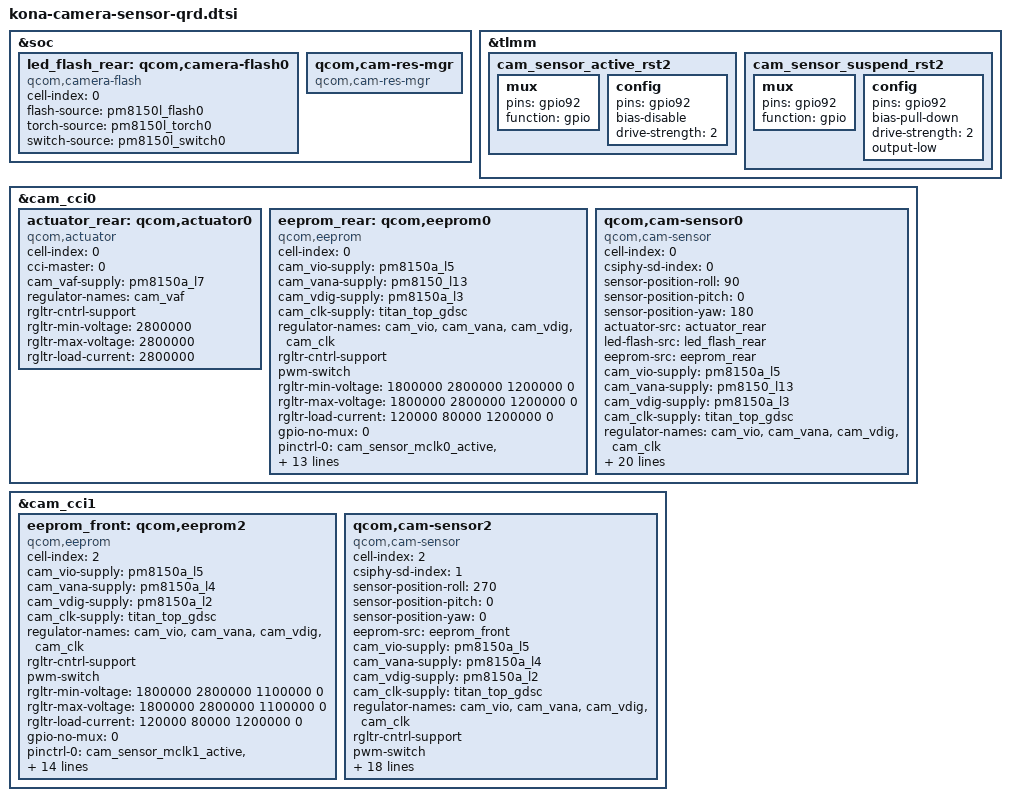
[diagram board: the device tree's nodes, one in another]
&soc {

	led_flash_rear: qcom,camera-flash0 {
		cell-index = <0>;
		compatible = "qcom,camera-flash";
		flash-source = <&pm8150l_flash0>;
		torch-source = <&pm8150l_torch0>;
		switch-source = <&pm8150l_switch0>;
		status = "ok";
	};

	qcom,cam-res-mgr {
		compatible = "qcom,cam-res-mgr";
		status = "ok";
	};
};

&tlmm {

	cam_sensor_active_rst2: cam_sensor_active_rst2 {
		mux {
			pins = "gpio92";
			function = "gpio";
		};

		config {
			pins = "gpio92";
			bias-disable;
			drive-strength = <2>;
		};
	};

	cam_sensor_suspend_rst2: cam_sensor_suspend_rst2 {
		mux {
			pins = "gpio92";
			function = "gpio";
		};

		config {
			pins = "gpio92";
			bias-pull-down;
			drive-strength = <2>;
			output-low;
		};
	};
};

&cam_cci0 {

	actuator_rear: qcom,actuator0 {
		cell-index = <0>;
		compatible = "qcom,actuator";
		cci-master = <0>;
		cam_vaf-supply = <&pm8150a_l7>;
		regulator-names = "cam_vaf";
		rgltr-cntrl-support;
		rgltr-min-voltage = <2800000>;
		rgltr-max-voltage = <2800000>;
		rgltr-load-current = <2800000>;
	};

	eeprom_rear: qcom,eeprom0 {
		cell-index = <0>;
		compatible = "qcom,eeprom";
		cam_vio-supply = <&pm8150a_l5>;
		cam_vana-supply = <&pm8150_l13>;
		cam_vdig-supply = <&pm8150a_l3>;
		cam_clk-supply = <&titan_top_gdsc>;
		regulator-names = "cam_vio", "cam_vana", "cam_vdig", "cam_clk";
		rgltr-cntrl-support;
		pwm-switch;
		rgltr-min-voltage = <1800000 2800000 1200000 0>;
		rgltr-max-voltage = <1800000 2800000 1200000 0>;
		rgltr-load-current = <120000 80000 1200000 0>;
		gpio-no-mux = <0>;
		pinctrl-names = "cam_default", "cam_suspend";
		pinctrl-0 = <&cam_sensor_mclk0_active>, <&cam_sensor_active_rear>;
		pinctrl-1 = <&cam_sensor_mclk0_suspend>, <&cam_sensor_suspend_rear>;
		gpios = <&tlmm 94 GPIO_ACTIVE_HIGH>, <&tlmm 93 GPIO_ACTIVE_HIGH>;
		gpio-reset = <1>;
		gpio-req-tbl-num = <0 1>;
		gpio-req-tbl-flags = <1 0>;
		gpio-req-tbl-label = "CAMIF_MCLK0", "CAM_RESET0";
		sensor-mode = <0>;
		cci-master = <0>;
		status = "ok";
		clocks = <&clock_camcc CAM_CC_MCLK0_CLK>;
		clock-names = "cam_clk";
		clock-cntl-level = "turbo";
		clock-rates = <24000000>;
	};

	qcom,cam-sensor0 {
		cell-index = <0>;
		compatible = "qcom,cam-sensor";
		csiphy-sd-index = <0>;
		sensor-position-roll = <90>;
		sensor-position-pitch = <0>;
		sensor-position-yaw = <180>;
		actuator-src = <&actuator_rear>;
		led-flash-src = <&led_flash_rear>;
		eeprom-src = <&eeprom_rear>;
		cam_vio-supply = <&pm8150a_l5>;
		cam_vana-supply = <&pm8150_l13>;
		cam_vdig-supply = <&pm8150a_l3>;
		cam_clk-supply = <&titan_top_gdsc>;
		regulator-names = "cam_vio", "cam_vana", "cam_vdig", "cam_clk";
		rgltr-cntrl-support;
		pwm-switch;
		rgltr-min-voltage = <1800000 2800000 1200000 0>;
		rgltr-max-voltage = <1800000 2800000 1200000 0>;
		rgltr-load-current = <120000 80000 1200000 0>;
		gpio-no-mux = <0>;
		pinctrl-names = "cam_default", "cam_suspend";
		pinctrl-0 = <&cam_sensor_mclk0_active>, <&cam_sensor_active_rear>;
		pinctrl-1 = <&cam_sensor_mclk0_suspend>, <&cam_sensor_suspend_rear>;
		gpios = <&tlmm 94 GPIO_ACTIVE_HIGH>, <&tlmm 93 GPIO_ACTIVE_HIGH>;
		gpio-reset = <1>;
		gpio-req-tbl-num = <0 1>;
		gpio-req-tbl-flags = <1 0>;
		gpio-req-tbl-label = "CAMIF_MCLK0", "CAM_RESET0";
		sensor-mode = <0>;
		cci-master = <0>;
		status = "ok";
		clocks = <&clock_camcc CAM_CC_MCLK0_CLK>;
		clock-names = "cam_clk";
		clock-cntl-level = "turbo";
		clock-rates = <24000000>;
	};
};

&cam_cci1 {

	eeprom_front: qcom,eeprom2 {
		cell-index = <2>;
		compatible = "qcom,eeprom";
		cam_vio-supply = <&pm8150a_l5>;
		cam_vana-supply = <&pm8150a_l4>;
		cam_vdig-supply = <&pm8150a_l2>;
		cam_clk-supply = <&titan_top_gdsc>;
		regulator-names = "cam_vio", "cam_vana", "cam_vdig", "cam_clk";
		rgltr-cntrl-support;
		pwm-switch;
		rgltr-min-voltage = <1800000 2800000 1100000 0>;
		rgltr-max-voltage = <1800000 2800000 1100000 0>;
		rgltr-load-current = <120000 80000 1200000 0>;
		gpio-no-mux = <0>;
		pinctrl-names = "cam_default", "cam_suspend";
		pinctrl-0 = <&cam_sensor_mclk1_active>, <&cam_sensor_active_rst2>;
		pinctrl-1 = <&cam_sensor_mclk1_suspend>, <&cam_sensor_suspend_rst2>;
		gpios = <&tlmm 95 GPIO_ACTIVE_HIGH>, <&tlmm 92 GPIO_ACTIVE_HIGH>;
		gpio-reset = <1>;
		gpio-req-tbl-num = <0 1>;
		gpio-req-tbl-flags = <1 0>;
		gpio-req-tbl-label = "CAMIF_MCLK1", "CAM_RESET2";
		sensor-position = <1>;
		sensor-mode = <0>;
		cci-master = <0>;
		status = "ok";
		clocks = <&clock_camcc CAM_CC_MCLK1_CLK>;
		clock-names = "cam_clk";
		clock-cntl-level = "turbo";
		clock-rates = <24000000>;
	};

	qcom,cam-sensor2 {
		cell-index = <2>;
		compatible = "qcom,cam-sensor";
		csiphy-sd-index = <1>;
		sensor-position-roll = <270>;
		sensor-position-pitch = <0>;
		sensor-position-yaw = <0>;
		eeprom-src = <&eeprom_front>;
		cam_vio-supply = <&pm8150a_l5>;
		cam_vana-supply = <&pm8150a_l4>;
		cam_vdig-supply = <&pm8150a_l2>;
		cam_clk-supply = <&titan_top_gdsc>;
		regulator-names = "cam_vio", "cam_vana", "cam_vdig", "cam_clk";
		rgltr-cntrl-support;
		pwm-switch;
		rgltr-min-voltage = <1800000 2800000 1100000 0>;
		rgltr-max-voltage = <1800000 2800000 1100000 0>;
		rgltr-load-current = <120000 80000 1200000 0>;
		gpio-no-mux = <0>;
		pinctrl-names = "cam_default", "cam_suspend";
		pinctrl-0 = <&cam_sensor_mclk1_active>, <&cam_sensor_active_rst2>;
		pinctrl-1 = <&cam_sensor_mclk1_suspend>, <&cam_sensor_suspend_rst2>;
		gpios = <&tlmm 95 GPIO_ACTIVE_HIGH>, <&tlmm 92 GPIO_ACTIVE_HIGH>;
		gpio-reset = <1>;
		gpio-req-tbl-num = <0 1>;
		gpio-req-tbl-flags = <1 0>;
		gpio-req-tbl-label = "CAMIF_MCLK1", "CAM_RESET2";
		sensor-mode = <0>;
		cci-master = <0>;
		status = "ok";
		clocks = <&clock_camcc CAM_CC_MCLK1_CLK>;
		clock-names = "cam_clk";
		clock-cntl-level = "turbo";
		clock-rates = <24000000>;
	};
};
